# f28004x_cla_prom_crc32_regs register map
Vendor: Texas Instruments
Peripheral module from a debugger description file (folder C2000).
Address unit: 16 bits
Registers are 32-bit, read-write, no defined reset value unless marked. A register's access mark holds for its fields unless they carry their own. Offsets are as the file gives them; lines under a group give offsets from that group; [hi:lo] are bit positions; {n}, {i} and the like mark numbered series; 'fields as' and 'values as' point back to an identical list; <NAME> marks a mode.

## CLA_PROM_CRC32_REGS — CLA PROM CRC32 Registers
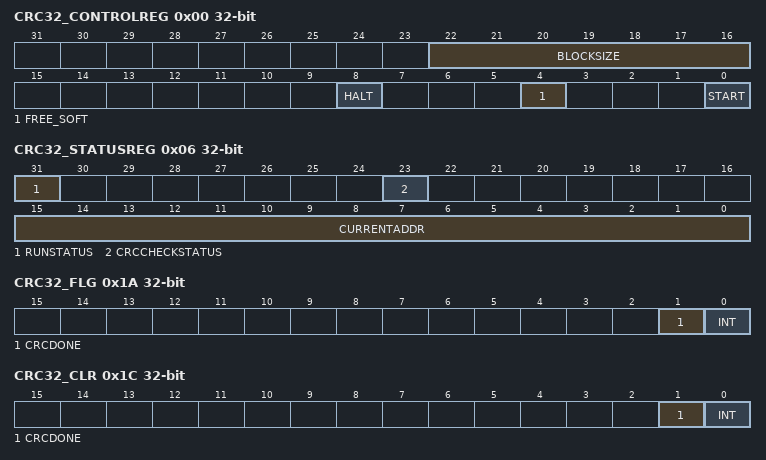
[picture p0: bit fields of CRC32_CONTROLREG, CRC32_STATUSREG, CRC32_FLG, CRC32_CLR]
0x00 CRC32_CONTROLREG — CRC32-Control Register
  [22:16] BLOCKSIZE — Block size of ROM for which CRC is to be calculated
  [8] HALT — Halt Bit
  [4] FREE_SOFT — emulation control bit
  [0] START — Start Bit
0x02 CRC32_STARTADDRESS
  [31:0] START_ADDRESS
0x04 CRC32_SEED
  [31:0] SEED — Initial CRC value
0x06 CRC32_STATUSREG ro — CRC32-Status Register
  [31] RUNSTATUS — CRC active status
  [23] CRCCHECKSTATUS — CRC active status
  [15:0] CURRENTADDR — Point to the data fetch unit current address
0x08 CRC32_CRCRESULT ro
0x0A CRC32_GOLDENCRC
0x18 CRC32_INTEN — CRC32-Interrupt enable register
  [1] CRCDONE — CRCDONE interrupt enable register
0x1A CRC32_FLG ro — CRC32-Interrupt Flag Register
  [1] CRCDONE — CRCDONE Interrupt status flag
  [0] INT — Global Interrupt status flag
0x1C CRC32_CLR — CRC32-Interrupt Clear Register
  [1] CRCDONE — CRCDONE Interrupt clear
  [0] INT — Global Interrupt clear
0x1E CRC32_FRC — CRC32-Interrupt Force Register
  [1] CRCDONE — CRCDONE Interrupt force
